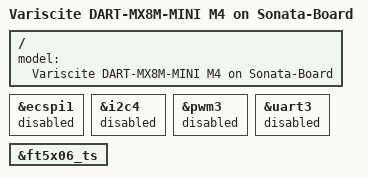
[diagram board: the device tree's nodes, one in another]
// SPDX-License-Identifier: (GPL-2.0+ OR MIT)
/*
 * Copyright 2019 NXP
 * Copyright 2019-2026 Variscite Ltd.
 */

#include "imx8mm-var-dart-sonata.dts"
#include "imx8mm-var-m4.dtsi"

/ {
	model = "Variscite DART-MX8M-MINI M4 on Sonata-Board";
};

/* M4 may use ECSPI1, GPIO4, GPT1, I2C4, WDOG1, PWM3, SDMA1/3, and UART3. */
&ecspi1 {
	status = "disabled";
};

&i2c4 {
	status = "disabled";
};

&pwm3 {
	status = "disabled";
};

&uart3 {
	status = "disabled";
};

&ft5x06_ts {
	/delete-property/ reset-gpios;
};
